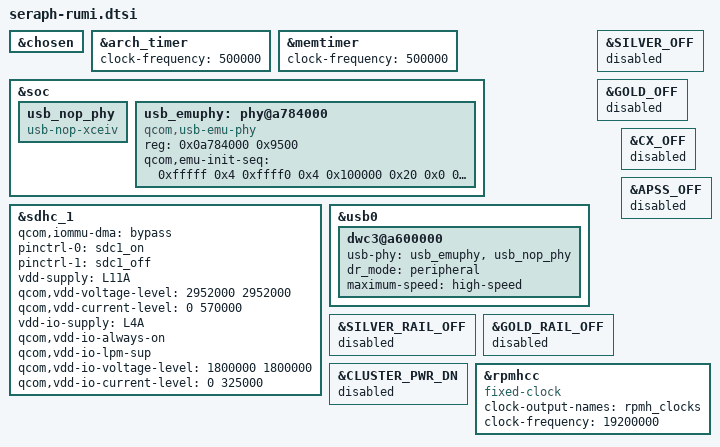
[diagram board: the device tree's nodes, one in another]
&chosen {
};

&arch_timer {
	clock-frequency = <500000>;
};

&memtimer {
	clock-frequency = <500000>;
};

&soc {
	usb_nop_phy: usb_nop_phy {
		compatible = "usb-nop-xceiv";
	};

	usb_emuphy: phy@a784000 {
		compatible = "qcom,usb-emu-phy";
		reg = <0x0a784000 0x9500>;

		qcom,emu-init-seq = <0xfffff 0x4
			0xffff0 0x4
			0x100000 0x20
			0x0 0x20
			0x000101F0 0x20
			0x00100000 0x3c
			0x0 0x3c
			0x0 0x4>;
	};
};

&sdhc_1 {
	status = "ok";

	qcom,iommu-dma = "bypass";

	pinctrl-names = "default", "sleep";
	pinctrl-0 = <&sdc1_on>;
	pinctrl-1 = <&sdc1_off>;

	vdd-supply = <&L11A>;
	qcom,vdd-voltage-level = <2952000 2952000>;
	qcom,vdd-current-level = <0 570000>;

	vdd-io-supply = <&L4A>;
	qcom,vdd-io-always-on;
	qcom,vdd-io-lpm-sup;
	qcom,vdd-io-voltage-level = <1800000 1800000>;
	qcom,vdd-io-current-level = <0 325000>;
};

&usb0 {
	dwc3@a600000 {
		usb-phy = <&usb_emuphy>, <&usb_nop_phy>;
		dr_mode = "peripheral";
		maximum-speed = "high-speed";
	};
};

&SILVER_OFF {
	status = "disabled";
};

&SILVER_RAIL_OFF {
	status = "disabled";
};

&GOLD_OFF {
	status = "disabled";
};

&GOLD_RAIL_OFF {
	status = "disabled";
};

&CLUSTER_PWR_DN {
	status = "disabled";
};

&CX_OFF {
	status = "disabled";
};

&APSS_OFF {
	status = "disabled";
};

&rpmhcc {
	compatible = "fixed-clock";
	clock-output-names = "rpmh_clocks";
	clock-frequency = <19200000>;
};
